# MKW20Z4 register map
Vendor: Freescale Semiconductor, Inc.; Series: Kinetis_W; File version: 1.6
CPU: CM0PLUS r0p0, little endian, no MPU, no FPU, VTOR, 2 interrupt priority bits
Registers are 32-bit, read-write, reset 0x0 unless marked. A register's access mark holds for its fields unless they carry their own. Offsets are from the block's base; [hi:lo] are bit positions.

## RSIM — Radio System Integration Module
Base 0x40059000; register names take the prefix RSIM_
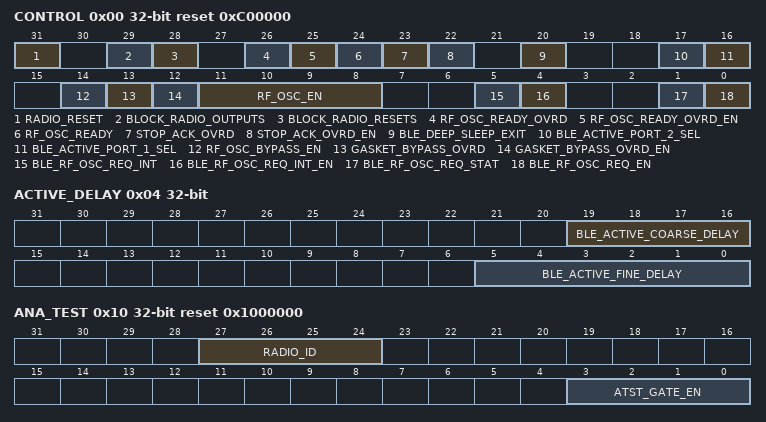
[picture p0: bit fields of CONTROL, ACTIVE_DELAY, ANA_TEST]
0x00 CONTROL reset 0xC00000 — RSIM Control
  [31] RADIO_RESET — Software Reset for the Radio
  [29] BLOCK_RADIO_OUTPUTS
  [28] BLOCK_RADIO_RESETS
  [26] RF_OSC_READY_OVRD — RF Ref Osc Ready Override
  [25] RF_OSC_READY_OVRD_EN — RF Ref Osc Ready Override Enable
  [24] RF_OSC_READY ro — RF Ref Osc Ready
  [23] STOP_ACK_OVRD — Stop Acknowledge Override
  [22] STOP_ACK_OVRD_EN — Stop Acknowledge Override Enable
  [20] BLE_DEEP_SLEEP_EXIT
  [17] BLE_ACTIVE_PORT_2_SEL — BLE Active port 2 select
  [16] BLE_ACTIVE_PORT_1_SEL — BLE Active port 1 select
  [14] RF_OSC_BYPASS_EN — RF Ref Osc Bypass Enable
  [13] GASKET_BYPASS_OVRD — Gasket Bypass Override
  [12] GASKET_BYPASS_OVRD_EN — Gasket Bypass Override Enable
  [11:8] RF_OSC_EN — RF Ref Osc Enable [3:0]
    0=RF Ref Osc will be controlled by the SoC or the BLE link layer; 1=RF Ref Osc on in Run/Wait; 3=RF Ref Osc on in Stop; 7=RF Ref Osc on in VLPR/VLPW; 15=RF Ref Osc on in VLPS
  [5] BLE_RF_OSC_REQ_INT — BLE Ref Osc (Sysclk) Request Interrupt Flag
  [4] BLE_RF_OSC_REQ_INT_EN — BLE Ref Osc (Sysclk) Request Interrupt Enable
  [1] BLE_RF_OSC_REQ_STAT ro — BLE Ref Osc (Sysclk) Request Status
  [0] BLE_RF_OSC_REQ_EN — BLE Ref Osc (Sysclk) Request Enable
0x04 ACTIVE_DELAY — RSIM BLE Active Delay
  [19:16] BLE_ACTIVE_COARSE_DELAY, [5:0] BLE_ACTIVE_FINE_DELAY
0x08 MAC_MSB ro — RSIM MAC MSB
  [7:0] MAC_ADDR_MSB — MAC Address MSB
0x0C MAC_LSB ro — RSIM MAC LSB
  [31:0] MAC_ADDR_LSB — MAC Address LSB
0x10 ANA_TEST reset 0x1000000 — RSIM Analog Test
  [27:24] RADIO_ID ro — Radio Version ID number
    1=Apache 1.0; 2=Apache 1.1; 3=Apache 2.0
  [3:0] ATST_GATE_EN — ATST Transmission Gate Enables

## DCDC — DC to DC Converter
Base 0x4005A000; register names take the prefix DCDC_
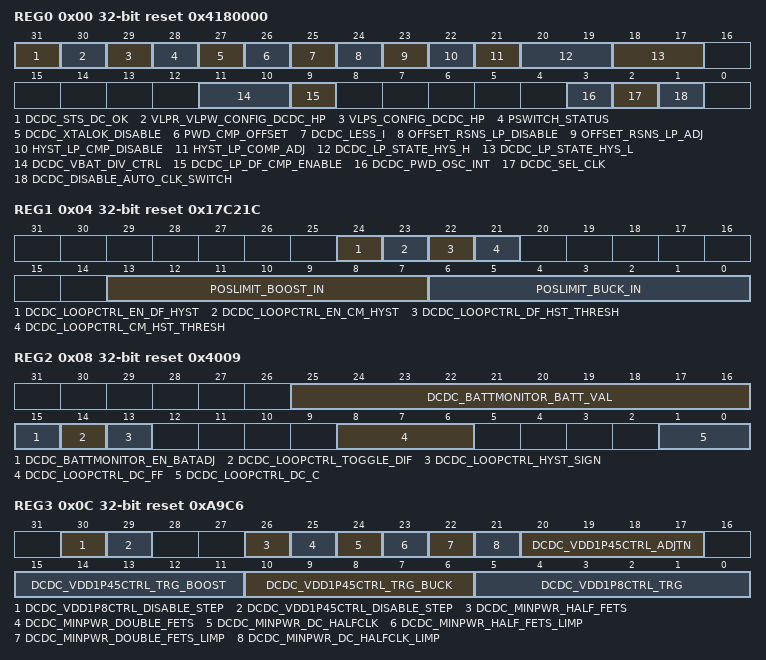
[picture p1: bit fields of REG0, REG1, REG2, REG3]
0x00 REG0 reset 0x4180000 — DCDC REGISTER 0
  [31] DCDC_STS_DC_OK ro
  [30] VLPR_VLPW_CONFIG_DCDC_HP
  [29] VLPS_CONFIG_DCDC_HP
  [28] PSWITCH_STATUS ro
  [27] DCDC_XTALOK_DISABLE
  [26] PWD_CMP_OFFSET
  [25] DCDC_LESS_I
  [24] OFFSET_RSNS_LP_DISABLE
  [23] OFFSET_RSNS_LP_ADJ
  [22] HYST_LP_CMP_DISABLE
  [21] HYST_LP_COMP_ADJ
  [20:19] DCDC_LP_STATE_HYS_H
    0=Target voltage value + 0 mV; 1=Target voltage value + 25 mV; 2=Target voltage value + 50 mV; 3=Target voltage value + 75 mV
  [18:17] DCDC_LP_STATE_HYS_L
    0=Target voltage value - 0 mV; 1=Target voltage value - 25 mV; 2=Target voltage value - 50 mV; 3=Target voltage value - 75 mV
  [11:10] DCDC_VBAT_DIV_CTRL
  [9] DCDC_LP_DF_CMP_ENABLE
  [3] DCDC_PWD_OSC_INT
  [2] DCDC_SEL_CLK
  [1] DCDC_DISABLE_AUTO_CLK_SWITCH
0x04 REG1 reset 0x17C21C — DCDC REGISTER 1
  [24] DCDC_LOOPCTRL_EN_DF_HYST, [23] DCDC_LOOPCTRL_EN_CM_HYST, [22] DCDC_LOOPCTRL_DF_HST_THRESH, [21] DCDC_LOOPCTRL_CM_HST_THRESH, [13:7] POSLIMIT_BOOST_IN, [6:0] POSLIMIT_BUCK_IN
0x08 REG2 reset 0x4009 — DCDC REGISTER 2
  [25:16] DCDC_BATTMONITOR_BATT_VAL, [15] DCDC_BATTMONITOR_EN_BATADJ, [14] DCDC_LOOPCTRL_TOGGLE_DIF, [13] DCDC_LOOPCTRL_HYST_SIGN, [8:6] DCDC_LOOPCTRL_DC_FF ro, [1:0] DCDC_LOOPCTRL_DC_C ro
0x0C REG3 reset 0xA9C6 — DCDC REGISTER 3
  [30] DCDC_VDD1P8CTRL_DISABLE_STEP
  [29] DCDC_VDD1P45CTRL_DISABLE_STEP
  [26] DCDC_MINPWR_HALF_FETS
  [25] DCDC_MINPWR_DOUBLE_FETS
  [24] DCDC_MINPWR_DC_HALFCLK
  [23] DCDC_MINPWR_HALF_FETS_LIMP
  [22] DCDC_MINPWR_DOUBLE_FETS_LIMP
  [21] DCDC_MINPWR_DC_HALFCLK_LIMP
  [20:17] DCDC_VDD1P45CTRL_ADJTN
  [15:11] DCDC_VDD1P45CTRL_TRG_BOOST
    21=1.8 V; 15=1.65 V; 7=1.45 V; 0=1.275 V
  [10:6] DCDC_VDD1P45CTRL_TRG_BUCK
    15=1.65 V; 7=1.45 V; 0=1.275 V
  [5:0] DCDC_VDD1P8CTRL_TRG
    0=1.65 V; 6=1.8 V; 17=2.075 V; 32=2.8 V; 52=3.3 V; 63=3.575 V
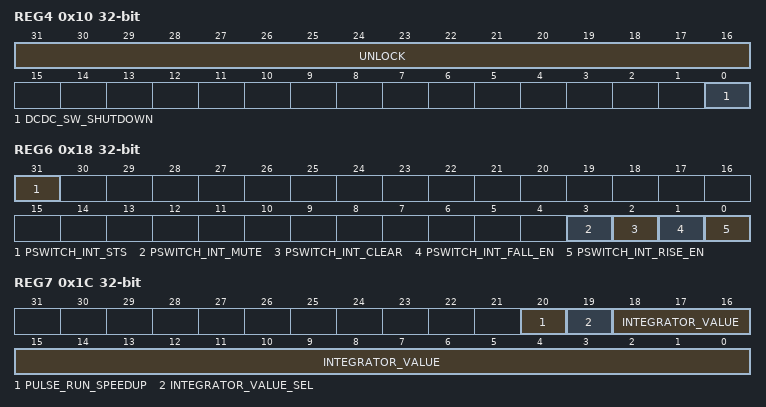
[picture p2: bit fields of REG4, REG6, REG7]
0x10 REG4 — DCDC REGISTER 4
  [31:16] UNLOCK
  [0] DCDC_SW_SHUTDOWN — Shut down DCDC in buck mode. DCDC can be turned on by pulling PSWITCH to high momentarily (min TBD us).
0x18 REG6 — DCDC REGISTER 6
  [31] PSWITCH_INT_STS ro, [3] PSWITCH_INT_MUTE, [2] PSWITCH_INT_CLEAR, [1] PSWITCH_INT_FALL_EN, [0] PSWITCH_INT_RISE_EN
0x1C REG7 — DCDC REGISTER 7
  [20] PULSE_RUN_SPEEDUP, [19] INTEGRATOR_VALUE_SEL, [18:0] INTEGRATOR_VALUE

## Notices in the file
Redistribution and use in source and binary forms, with or without modification,
are permitted provided that the following conditions are met:
o Redistributions of source code must retain the above copyright notice, this list
of conditions and the following disclaimer.
o Redistributions in binary form must reproduce the above copyright notice, this
list of conditions and the following disclaimer in the documentation and/or
other materials provided with the distribution.
o Neither the name of Freescale Semiconductor, Inc. nor the names of its
contributors may be used to endorse or promote products derived from this
software without specific prior written permission.
THIS SOFTWARE IS PROVIDED BY THE COPYRIGHT HOLDERS AND CONTRIBUTORS "AS IS" AND
ANY EXPRESS OR IMPLIED WARRANTIES, INCLUDING, BUT NOT LIMITED TO, THE IMPLIED
WARRANTIES OF MERCHANTABILITY AND FITNESS FOR A PARTICULAR PURPOSE ARE
DISCLAIMED. IN NO EVENT SHALL THE COPYRIGHT HOLDER OR CONTRIBUTORS BE LIABLE FOR
ANY DIRECT, INDIRECT, INCIDENTAL, SPECIAL, EXEMPLARY, OR CONSEQUENTIAL DAMAGES
(INCLUDING, BUT NOT LIMITED TO, PROCUREMENT OF SUBSTITUTE GOODS OR SERVICES;
LOSS OF USE, DATA, OR PROFITS; OR BUSINESS INTERRUPTION) HOWEVER CAUSED AND ON
ANY THEORY OF LIABILITY, WHETHER IN CONTRACT, STRICT LIABILITY, OR TORT
(INCLUDING NEGLIGENCE OR OTHERWISE) ARISING IN ANY WAY OUT OF THE USE OF THIS
SOFTWARE, EVEN IF ADVISED OF THE POSSIBILITY OF SUCH DAMAGE.
